# GPIO1 register map
Vendor: Texas Instruments
Peripheral module from a debugger description file (folder omap36xx).
Registers are 32-bit, read-write, reset 0x0 unless marked. A register's access mark holds for its fields unless they carry their own. Offsets are as the file gives them; lines under a group give offsets from that group; [hi:lo] are bit positions; {n}, {i} and the like mark numbered series; 'fields as' and 'values as' point back to an identical list; <NAME> marks a mode.

## GPIO1
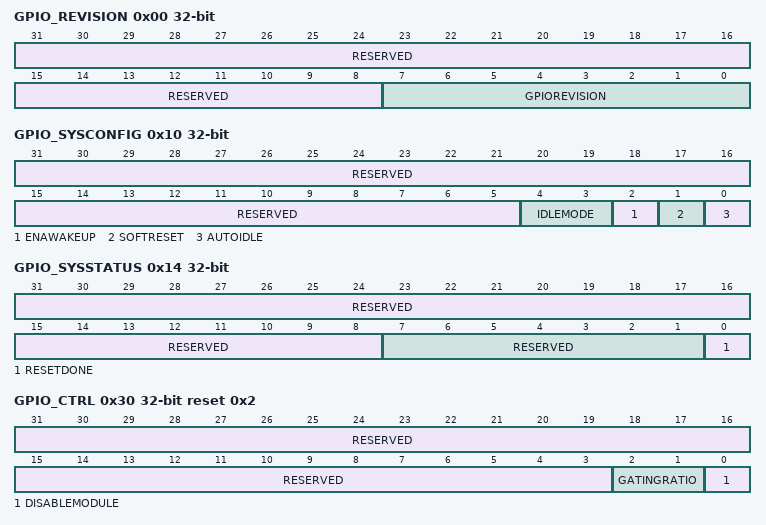
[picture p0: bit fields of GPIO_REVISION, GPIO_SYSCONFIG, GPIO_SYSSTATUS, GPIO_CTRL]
0x00 GPIO_REVISION ro (reset mask 0xFFFFFF00) — This register contains the IP revision code.
  [31:8] RESERVED — Read returns 0
  [7:0] GPIOREVISION — IP revision[7:4] Major revision . [3:0] Minor revision . Examples: 0x10 for 1.0, 0x21 for 2.1 .
0x10 GPIO_SYSCONFIG — This register controls the various parameters of the L4 interconnect.
  [31:5] RESERVED — Write 0s for future compatibility. Read returns 0
  [4:3] IDLEMODE — Power Management, Req/Ack control
    0=Force-idle. An idle request is acknowledged unconditionally; 1=No-idle. An idle request is never acknowledged; 2=Smart-idle. Acknowledgment to an idle request is given based on the internal activity of the module; 3=Reserved do not use
  [2] ENAWAKEUP — Wake-up capability enabled/disabled
    0=Wakeup disable; 1=Wakeup enable
  [1] SOFTRESET — Software reset. This bit is automatically reset by the hardware. During reads, it always returns 0.
    0=Normal mode; 1=The module is reset
  [0] AUTOIDLE — Internal interface clock gating strategy
    0=Interface clock is free-running; 1=Automatic interface clock gating strategy is applied, based on the L4 interconnect activity
0x14 GPIO_SYSSTATUS ro (reset mask 0xFFFFFFFE) — This register provides status information about the module, excluding the interrupt-status information.
  [31:8] RESERVED — Read returns 0
  [7:1] RESERVED — Read returns 0
  [0] RESETDONE — Internal reset monitoring
    0=Internal module reset in on-going; 1=Reset completed
0x18 GPIO_IRQSTATUS1 — This register provides IRQ 1 status information.
  [31:0] IRQSTATUS1 — Interrupt 1 Status Register. Write a 1 in the corresponding bit to clear it to 0. Write 0 in the corresponding bit does not affect its value.
    0=IRQ channel N not triggered; 1=IRQ channel N triggered
0x1C GPIO_IRQENABLE1 — This register provides IRQ 1 enable information.
  [31:0] IRQENABLE1 — Interrupt 1 Enable Register
    0=Disable IRQ generation for channel N; 1=Enable IRQ generation for channel N
0x20 GPIO_WAKEUPENABLE — This register provides wakeup-enable information.
  [31:0] WAKEUPEN — Wake Up Enable Register
    0=Disable wake-up generation for channel N; 1=Enable wake-up generation for channel N
0x28 GPIO_IRQSTATUS2 — This register provides IRQ 2 status information.
  [31:0] IRQSTATUS2 — Interrupt 2 Status Register. Write a 1 in the corresponding bit to clear it to 0. Write 0 in the corresponding bit does not affect its value.
    0=IRQ channel N not triggered; 1=IRQ channel N triggered
0x2C GPIO_IRQENABLE2 — This register provides IRQ 2 enable information.
  [31:0] IRQENABLE2 — Interrupt 2 Enable Register
    values as GPIO_IRQENABLE1.IRQENABLE1
0x30 GPIO_CTRL reset 0x2 — This register controls the clock gating functionality.
  [31:3] RESERVED — Read returns 0
  [2:1] GATINGRATIO
    0=Functional clock is interface clock; 1=Functional clock is interface clock divided by 2; 2=Functional clock is interface clock divided by 4; 3=Functional clock is interface clock divided by 8
  [0] DISABLEMODULE — Module Disable
    0=Module is enabled, clocks are not gated; 1=Module is disabled, clocks are gated
0x34 GPIO_OE reset 0xFFFFFFFF — This register is used to enable the pins output capabilities. Its only function is to carry the pads configuration.
  [31:0] OUTPUTEN — Output Data Enable
    0=The corresponding GPIO port is configured as output; 1=The corresponding GPIO port is configured as input
0x38 GPIO_DATAIN ro — This register is used to register the data that is read from the GPIO pins.
  [31:0] DATAINPUT — Sampled Input Data
0x3C GPIO_DATAOUT — This register is used for setting the value of the GPIO output pins
  [31:0] DATAOUTPUT — Output Data
0x40 GPIO_LEVELDETECT0 — This register is used to enable/disable for each input lines the low-level (0) detection to be used for the interrupt request generation.
  [31:0] LOWLEVEL — Low Level Interrupt Enable
    0=Disable the IRQ assertion on low-level detect; 1=Enable the IRQ assertion on low-level detect
0x44 GPIO_LEVELDETECT1 — This register is used to enable/disable for each input lines the high-level (1) detection to be used for the interrupt request generation.
  [31:0] HIGHLEVEL — High Level Interrupt Enable
    0=Disable the IRQ assertion on high-level detect; 1=Enable the IRQ assertion on high-level detect
0x48 GPIO_RISINGDETECT — This register is used to enable/disable for each input lines the rising-edge (transition 0=>1) detection to be used for the interrupt request and the wake-up generation.
  [31:0] RISINGEDGE — Rising Edge Interrupt/wake-up enable
    0=Disable IRQ /wake up on rising edge detect; 1=Enable IRQ /wake up on rising edge detect
0x4C GPIO_FALLINGDETECT — This register is used to enable/disable for each input lines the falling-edge (transition 1=>0) detection to be used for the interrupt request and the wake-up generation.
  [31:0] FALLINGEDGE — Falling Edge Interrupt/wake-up enable
    0=Disable IRQ/wakeup on falling edge detect; 1=Enable IRQ /wake up on falling edge detect
0x50 GPIO_DEBOUNCENABLE — This register is used to enable/disable the debouncing feature for each input line.
  [31:0] DEBOUNCEEN — Input Debounce Enable
    0=Disable debouncing feature on the corresponding input port; 1=Enable debouncing feature on the corresponding input port
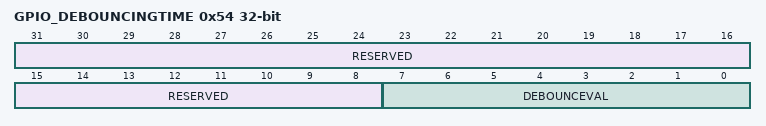
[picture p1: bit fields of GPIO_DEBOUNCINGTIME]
0x54 GPIO_DEBOUNCINGTIME — This register controls debouncing time (the value is global for all ports).
  [31:8] RESERVED — Read returns 0
  [7:0] DEBOUNCEVAL — Input Debouncing Value in 31 microsecond steps. debouncing time = (DEBOUNCEVAL+1) x 31 μs
0x60 GPIO_CLEARIRQENABLE1 — Clear to 0 the corresponding bits in the register
  [31:0] CLEARIRQEN1 — Clear Interrupt Enable 1
    0=No effect; 1=Clear the corresponding bit in the register
0x64 GPIO_SETIRQENABLE1 — Set to 1 the corresponding bits in the register
  [31:0] SETIRQEN1 — Set Interrupt Enable 1
    0=No effect; 1=Set the corresponding bit in the register
0x70 GPIO_CLEARIRQENABLE2 — Clear to 0 the corresponding bits in the register
  [31:0] CLEARIRQEN2 — Clear Interrupt Enable 2
    0=No effect; 1=Clear the corresponding bit in the register
0x74 GPIO_SETIRQENABLE2 — Set to 1 the corresponding bits in the register
  [31:0] SETIRQEN2 — Set Interrupt Enable 2
    0=No effect; 1=Set the corresponding bit in the register
0x80 GPIO_CLEARWKUENA — Clear to 0 the corresponding bits in the register
  [31:0] CLEARWAKEUPEN — Clear wake-up enable
    0=No effect; 1=Clear the corresponding bit in the register
0x84 GPIO_SETWKUENA — Set to 1 the corresponding bits in the register
  [31:0] SETWAKEUPEN — Set wake-up enable
    0=No effect; 1=Set the corresponding bit in the register
0x90 GPIO_CLEARDATAOUT — Clear to 0 the corresponding bits in the register
  [31:0] CLEARDATAOUT — Clear Data Output Register
    0=No effect; 1=Clear the corresponding bit in the register
0x94 GPIO_SETDATAOUT — Set to 1 the corresponding bits in the register
  [31:0] SETDATAOUT — Set Data Output Register
    0=No effect; 1=Set the corresponding bit in the register
